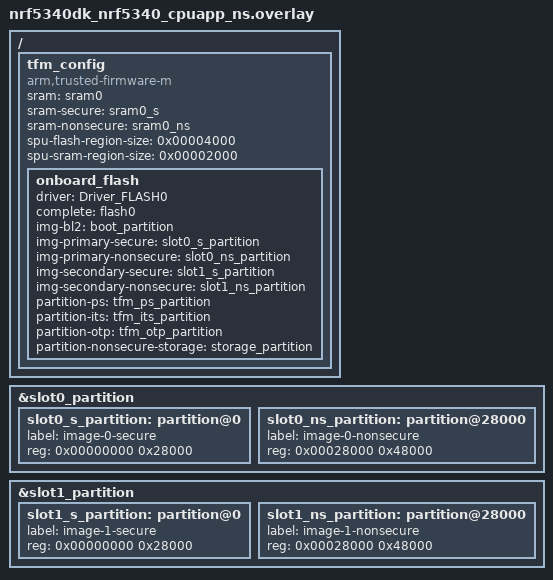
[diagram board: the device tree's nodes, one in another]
/*
 * Copyright (c) 2025 Embeint Holdings Pty Ltd
 * SPDX-License-Identifier: FSL-1.1-ALv2
 */

#include <common/nordic/infuse_nrf5340_cpuapp_ns.dtsi>
#include "nrf5340dk_nrf5340_cpuapp_common.dtsi"

/ {
	tfm_config {
		compatible = "arm,trusted-firmware-m";
		sram = <&sram0>;
		sram-secure = <&sram0_s>;
		sram-nonsecure = <&sram0_ns>;
		spu-flash-region-size = <0x00004000>;
		spu-sram-region-size = <0x00002000>;

		onboard_flash {
			driver = "Driver_FLASH0";
			complete = <&flash0>;
			img-bl2 = <&boot_partition>;
			img-primary-secure = <&slot0_s_partition>;
			img-primary-nonsecure = <&slot0_ns_partition>;
			img-secondary-secure = <&slot1_s_partition>;
			img-secondary-nonsecure = <&slot1_ns_partition>;
			partition-ps = <&tfm_ps_partition>;
			partition-its = <&tfm_its_partition>;
			partition-otp = <&tfm_otp_partition>;
			partition-nonsecure-storage = <&storage_partition>;
		};
	};
};

/* Allocate more ROM to non-secure application */
/delete-node/ &slot0_s_partition;
/delete-node/ &slot0_ns_partition;
/delete-node/ &slot1_s_partition;
/delete-node/ &slot1_ns_partition;

&slot0_partition {
	slot0_s_partition: partition@0 {
		label = "image-0-secure";
		reg = <0x00000000 0x28000>;
	};

	slot0_ns_partition: partition@28000 {
		label = "image-0-nonsecure";
		reg = <0x00028000 0x48000>;
	};
};

&slot1_partition {
	slot1_s_partition: partition@0 {
		label = "image-1-secure";
		reg = <0x00000000 0x28000>;
	};

	slot1_ns_partition: partition@28000 {
		label = "image-1-nonsecure";
		reg = <0x00028000 0x48000>;
	};
};
